# S32R372 register map
Vendor: Freescale Semiconductor, Inc.; Series: Qorivva; File version: 1.6
Registers are 32-bit, read-write, reset 0x0 unless marked. A register's access mark holds for its fields unless they carry their own. Offsets are from the block's base; [hi:lo] are bit positions; {n}, {i} and the like mark numbered series; 'fields as' and 'values as' point back to an identical list.

## STCU2
Base 0xFFF44000; register names take the prefix STCU2_
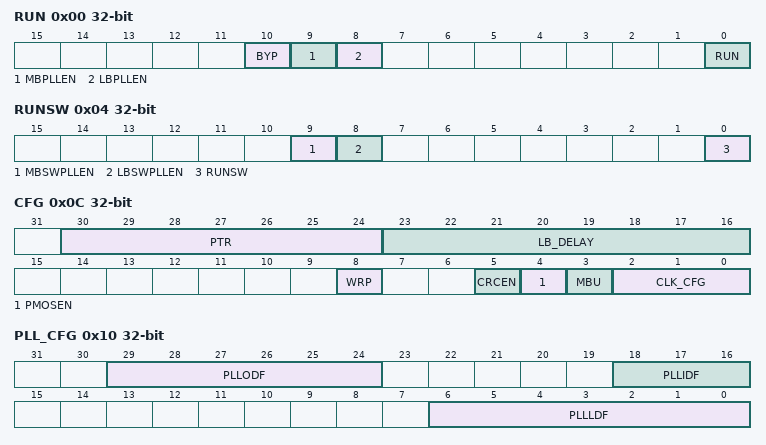
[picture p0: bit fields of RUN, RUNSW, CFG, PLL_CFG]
0x00 RUN — STCU2 Run Register
  [10] BYP — Bypass mode
    0=Off-Line Self-Test is active. In case the RUN bit into the STCU2_RUN register is not set before the Hard-Coded WDG Time-out, the WDTO error is generated into the STCU2_ERR_STAT register.; 1=Off-Line Self-Test is completely bypassed and the access to STCU2 is locked until the STCU2_SKC register is written according to the request access mode
  [9] MBPLLEN — Off-Line MBIST with PLL Enabled
    0=Off-Line MBIST is executed without using the on-chip PLL; 1=Off-Line MBIST is executed enabling the on-chip PLL control interface selecting the parameters defined into STCU2_PLL_CFG register
  [8] LBPLLEN — Off-Line LBIST with PLL Enabled
    0=Off-Line LBIST is executed without using the on-chip PLL; 1=Off-Line LBIST is executed enabling the on-chip PLL control interface selecting the parameters defined into STCU2_PLL_CFG register
  [0] RUN — RUN: RUN The RUN bit is automatically cleared by the STCU2 when the off-line self testing procedure has been completed
    0=Idle; 1=Off-Line Self testing procedure is running
0x04 RUNSW — STCU2 Run Software Register
  [9] MBSWPLLEN — On-Line MBIST with PLL Enabled
    0=On-Line MBIST is executed without using the on-chip PLL; 1=On-Line MBIST is executed using the PLL configuration provided by software. STCU2 does not take the PLL control but monitors the PLL lock signal to check if PLL is working correctly.
  [8] LBSWPLLEN — On-Line LBIST with PLL Enabled
    0=On-Line LBIST is executed without using the on-chip PLL; 1=On-Line LBIST is executed using the PLL configuration provided by software. STCU2 does not take the PLL control but monitors the PLL lock signal to check if PLL is working correctly.
  [0] RUNSW — RUNSW The RUNSW bit is automatically cleared by the STCU2 when the on-line self testing procedure has been completed
    0=Idle; 1=On-line self testing procedure is running
0x08 SKC wo — STCU2 SK Code Register
  [31:0] SKC — STCU2 security key code for off-line Test = D3FEA98Bh: Key1 to unlock the write access the STCU2 = 2C015674h: Key2 to unlock the write access the STCU2 STCU2 security key code for on-line Test = 753F924Eh: Key1 to unlock the write access the STCU2 = 8AC06DB1h: Key2 to unlock the write access the STCU2
0x0C CFG reset not defined — STCU2 Configuration Register
  [30:24] PTR — LBIST or MBIST pointer PTR defines the logical pointer to the first LBIST or MBIST to be scheduled when the self testing procedure is enabled
  [23:16] LB_DELAY — Delay LBIST run LB_DELAY defines the delay between the LBIST starts when more than a single LBIST is selected to be executed concurrently with the purpose of smoothing the power consumption transient
  [8] WRP — Write Protection 0: Specific STCU2 registers can be written through IPS bus interface after Off-Line Self-Test sequence has been completed 1: Specific STCU2 registers cannot be written though IPS also after Off-Line Self-Test sequence has been completed preventing in such a way any user application write operation
  [5] CRCEN — CRCEN: CRC Enable comparison You can always read this field
    0=The CRC comparison is not performed and the STCU2_ERR_STAT.CRCS[SW] and STCU2_ERR_STAT.UF/RF global flags are not updated in case of mismatches between STCU2.CRCE and STCU2.CRCR values; 1=The CRC comparison is performed and the status is updated into the related flags of the STCU2_ERR_STAT register
  [4] PMOSEN — MBIST PMOS Test Enable When MBU is 1 then "Auto test" MBIST test type will be selected regardless of the setting of this field
    0=When MBU is 0 then selects the "Reduced test" MBIST test type; 1=When MBU is 0 then selects the "Full test" MBIST test type
  [3] MBU — MBIST MBU Test Enabled
    0=Either "Full test" or "Reduced test" MBIST test type will be selected according to the PMOSEN value; 1=Selects "Auto test" MBIST test type regardless of the PMOSEN value
  [2:0] CLK_CFG — Logic, Memory BIST and STCU2 core CLK Clock configuration CLK_CFG defines the ratio between the sys_clk and the TCK used to program both the LBIST and the MBIST and the STCU2 core clock
0x10 PLL_CFG reset not defined — STCU2 PLL Configuration Register
  [29:24] PLLODF — PLL Output Division Factor The value of this field drives the Output Division factor of the PLL embedded into the device
  [18:16] PLLIDF — PLL Input Division Factor The value of this field drives the Input Division factor of the PLL embedded into the device
  [6:0] PLLLDF — PLL Loop Division Factor The value of this field drives the Loop Division factor of the PLL embedded into the device
0x14 WDG — STCU2 Watchdog Granularity
  [31:0] WDGEOC — Watchdog End of Count Timer This value defines the time limit for offline and online self test execution to ensure correct operation within the allowed time
0x1C CRCE reset not defined — STCU2 CRC Expected Status Register
  [31:0] CRCE — CRC expected signature
0x20 CRCR ro — STCU2 CRC Read Status Register
  [31:0] CRCR — Read CRC signature
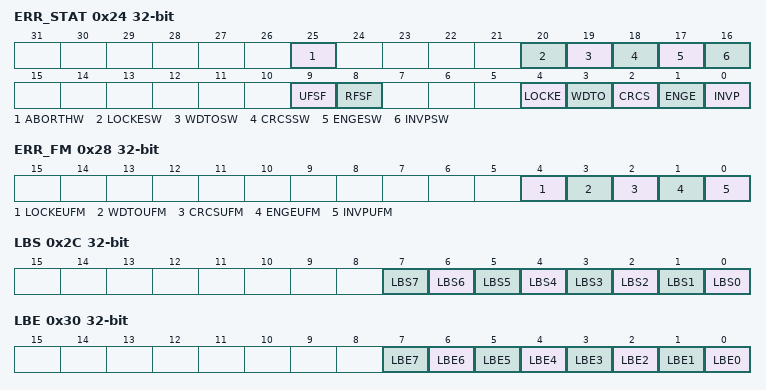
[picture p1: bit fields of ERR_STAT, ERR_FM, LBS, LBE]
0x24 ERR_STAT — STCU2 Error Register
  [25] ABORTHW ro — On-line hardware abort flag You can always read this field
    0=No hardware abort was requested during the On-Life Self-Test sequence; 1=A hardware abort was detected during the On-Life Self-Test sequence
  [20] LOCKESW ro — On-Line LOCK Error You can always read this field
    0=In case PLL is enabled, it is correctly locked during the Self-Test sequence; 1=When the PLL is enabled, this flag highlight that there has been an unexpected PLL unlock event during the On-Line Self-Test sequence execution. The On-Line Self-test run is stopped and the status of the current running LBISTs or MBISTs is saved into the related registers. The LOCK signal is monitored during the LBIST run when STCU2_RUNSW.LBSWPLLEN is set and/or during the MBIST run when STCU2_RUNSW[MBSWPLLEN] = 1.
  [19] WDTOSW ro — On-Line Watchdog time-out You can always read this field
    0=LBIST and MBIST time slot have been completed within the assigned watchdog time; 1=LBIST and MBIST time slot haven't been completed within the assigned watchdog time or there are internal mismatches among End of Execution signals. The conditions that flag the failures are the following: MBIST BEND status flags that at least one of the selected MBIST run is not finished lbist_done of the selected LBIST flags the LBIST run is/are not finished
  [18] CRCSSW ro — On-Line CRC Status This flag is activated ONLY when On-Line Self Test is performed and STCU2_CFG
    0=Successful CRC comparison or comparison has been masked (STCU2_CFG.CRCEN set to 0); 1=Failed CRC comparison
  [17] ENGESW ro — On-Line Engine Error You can always read this field
    0=Valid Engine execution; 1=Invalid Engine execution. The following conditions set this bit: STCU2 state machines (Watchdog, Master and Loader/Shifter) selects an unused code Serial pass/fail status of the selected MBIST and the global BBAD flag are not aligned Serial bend status of the selected MBIST and the global BEND flag are not aligned
  [16] INVPSW ro — On-Line Invalid Pointer You can always read this field
    0=Valid linked pointer list; 1=Invalid linked pointer list. The following conditions set this bit: Initial LBIST or MBIST pointer is out of range LBIST is selected when MBIST is concurrently running or vice versa Error in the LBIST/MBIST linking (execution generates an infinite loop)
  [9] UFSF — Unrecoverable Faults Status Flag This flag reports the global status of the UF
    0=No errors that trigger the Unrecoverable Faults condition; 1=There are errors that trigger the Unrecoverable Faults condition
  [8] RFSF — Recoverable Faults Status Flag This flag reports the global status of the RF
    0=No errors that trigger the Recoverable Faults condition; 1=There are errors that trigger the Recoverable Faults condition
  [4] LOCKE ro — Off-Line LOCK Error
    0=The PLL is correctly locked during the Self-Test sequence; 1=When the PLL is enabled, this flag highlights that there has been an unexpected PLL unlock event during the Off-Line Self-Test sequence execution. The Off-Line Self-test run is stopped and the status of the current running LBISTs or MBISTs is saved into the related registers. The LOCK signal is monitored during the LBIST run when STCU2_RUN[LBPLLEN] = 1 and/or during the MBIST run when STCU2_RUN[MBPLLEN] = 1.
  [3] WDTO ro — Off-Line Watchdog time-out
    0=LBIST and MBIST time slot have been completed within the assigned watchdog time; 1=LBIST and MBIST time slot haven't been completed within the assigned watchdog time or there are internal mismatches among End of Execution signals. The conditions that flag the failures are the following: The STCU2_RUN[RUN] bit or the STCU2_RUN[BYP] bit is not set before the Watchdog reaches the End of Count MBIST BEND status flags that at least one of the selected MBIST run is not finished lbist_done of the selected LBIST flags the LBIST run is/are not finished
  [2] CRCS ro — Off-Line CRC status This flag is activated ONLY when Off-Line Self Test is performed STCU2_CFG[CRCEN] is set to 1 otherwise it is always forced to 0 preventing in such a way the generation of the related STCU2_ERR_STAT
    0=Successful CRC comparison or comparison has been masked (STCU2_CFG[CRCEN] programmed to 0); 1=Failed CRC comparison
  [1] ENGE ro — Off-Line Engine Error
    values as ENGESW
  [0] INVP ro — Off-Line Invalid pointer
    values as INVPSW
0x28 ERR_FM reset not defined — STCU2 Error FM Register
  [4] LOCKEUFM — PLL LOCK Unrecoverable Fault Mapping
    0=Recoverable Fault Mapping; 1=Unrecoverable Fault Mapping
  [3] WDTOUFM — Watchdog time-out Unrecoverable Fault Mapping
    0=Recoverable Fault Mapping; 1=Unrecoverable Fault Mapping
  [2] CRCSUFM — CRC Status Unrecoverable Fault Mapping
    0=Recoverable Fault Mapping; 1=Unrecoverable Fault Mapping
  [1] ENGEUFM — Engine Error Unrecoverable fault Mapping
    0=Recoverable Fault Mapping; 1=Unrecoverable Fault Mapping
  [0] INVPUFM — Invalid Pointer Unrecoverable Fault Mapping
    0=Recoverable Fault Mapping; 1=Unrecoverable Mapping
0x2C LBS ro — STCU2 Off-Line LBIST Status Register
  [all] fields
    0=Failed LBIST execution; 1=Successful LBIST execution
  [n] LBS{n} (n=0..7) — Off-Line status of the selected LBIST
0x30 LBE ro — STCU2 Off-Line LBIST End Flag Register
  [all] fields
    0=LBIST execution not yet completed; 1=LBIST execution finished
  [n] LBE{n} (n=0..7) — Off-Line End status of the selected LBIST
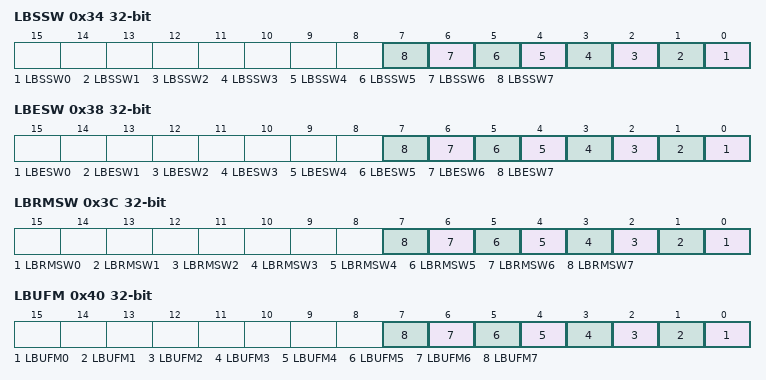
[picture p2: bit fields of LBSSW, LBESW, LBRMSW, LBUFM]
0x34 LBSSW ro — STCU2 On-Line LBIST Status Register
  [all] fields
    0=Failed LBIST execution; 1=Successful LBIST execution
  [n] LBSSW{n} (n=0..7) — LBSSWx: On-Line status of the selected LBIST
0x38 LBESW ro — STCU2 On-Line LBIST End Flag Register
  [all] fields
    values as the fields of LBE
  [n] LBESW{n} (n=0..7) — LBESWx: On-Line LBIST End status
0x3C LBRMSW reset not defined — STCU2 On-Line LBIST Reset Management
  [all] fields
    1=Global functional reset is pulsed at the end of LBIST run
  [n] LBRMSW{n} (n=0..7) — On-Line LBIST Reset Management In case one of the selected LBIST has this bit set to '1', then only the Global functional reset will be pulsed
0x40 LBUFM reset not defined — STCU2 LBIST Unrecoverable FM Register
  [all] fields
    0=Recoverable Fault mapping; 1=Unrecoverable Fault mapping
  [n] LBUFM{n} (n=0..7) — LBIST Unrecoverable Fault Mapping
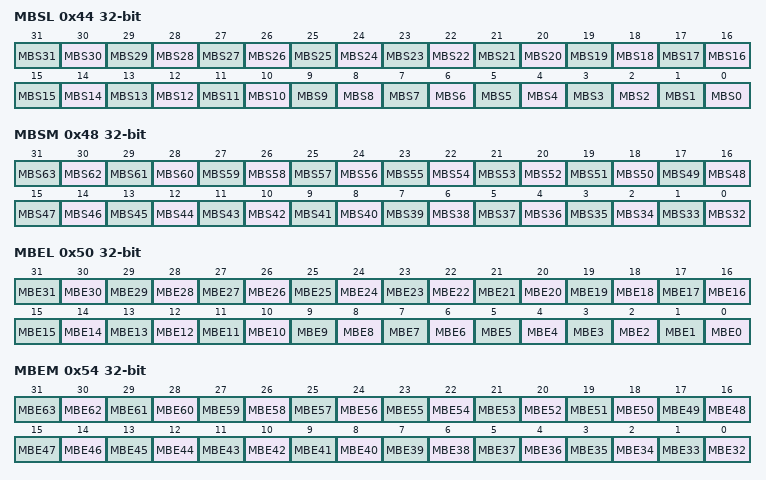
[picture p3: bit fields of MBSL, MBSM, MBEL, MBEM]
0x44 MBSL ro — STCU2 Off-Line MBIST Status Low Register
  [all] fields
    0=Failed NMCUT BIST execution; 1=No Fault detected during the NMCUT BIST execution
  [n] MBS{n} (n=0..31) — Off-Line status (NMCUT range = 0 to 31) of the selected MBIST This bit is meaningful when the related bit of the STCU2_MBEL register reports the MBIST is finished
0x48 MBSM ro — STCU2 Off-Line MBIST Status Medium Register
  [all] fields
    values as the fields of MBSL
  [n-32] MBS{n} (n=32..63) — MBSx: Off-Line status (NMCUT range = 32 to 63) of the selected MBIST This bit is meaningful when the related bit of the STCU2_MBEM register reports the MBIST is finished)
0x4C MBSH ro — STCU2 Off-Line MBIST Status High Register
  [0] MBS64 — Off-Line status (NMCUT range = 64 to 95) of the selected MBIST This bit is meaningful when the related bit of the STCU2_MBEH register reports the MBIST is finished)
    values as the fields of MBSL
0x50 MBEL ro — STCU2 Off-Line MBIST End Flag Low Register
  [all] fields
    0=MBIST execution still ongoing; 1=MBIST execution finished
  [n] MBE{n} (n=0..31) — Off-Line End status (0 to 31) of the selected MBIST
0x54 MBEM ro — STCU2 Off-Line MBIST End Flag Medium Register
  [all] fields
    0=MBIST execution still ongoing; 1=MBIST execution finished
  [n-32] MBE{n} (n=32..63) — Off-Line End status (32 to 63) of the selected MBIST
0x58 MBEH ro — STCU2 Off-Line MBIST End Flag High Register
  [0] MBE64 — MBEx: Off-Line End status (64 to 95) of the selected MBIST
    0=MBIST execution still ongoing; 1=MBIST execution finished
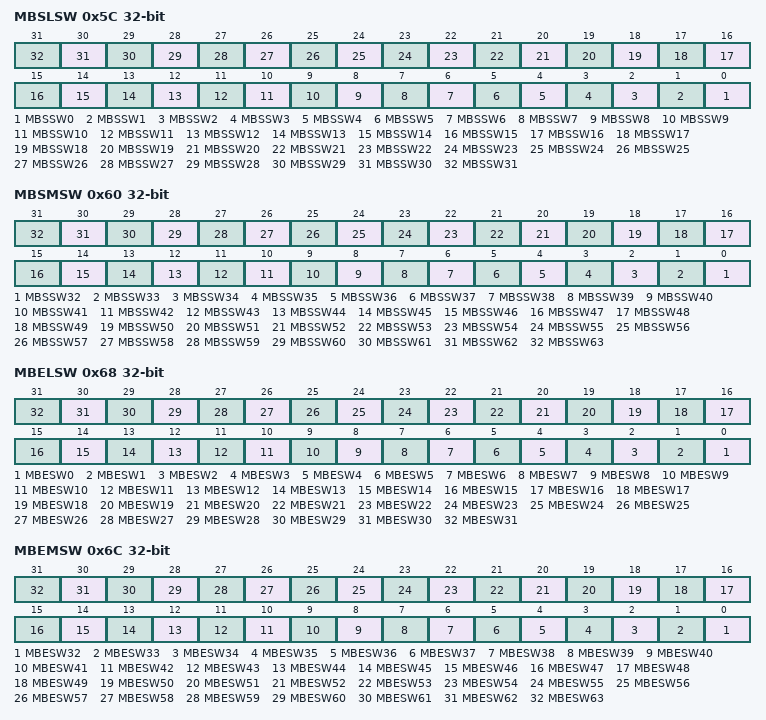
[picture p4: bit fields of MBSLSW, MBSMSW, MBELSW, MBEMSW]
0x5C MBSLSW ro — STCU2 On-Line MBIST Status Low Register
  [all] fields
    values as the fields of MBSL
  [n] MBSSW{n} (n=0..31) — On-Line status (NMCUT range = 0 to 31) of the selected MBIST
0x60 MBSMSW ro — STCU2 On-Line MBIST Status Medium Register
  [all] fields
    values as the fields of MBSL
  [n-32] MBSSW{n} (n=32..63) — MBSSWx: On-Line status (NMCUT range = 32 to 63) of the selected MBIST
0x64 MBSHSW ro — STCU2 On-Line MBIST Status High Register
  [0] MBSSW64 — MBSSWx: On-Line status (NMCUT range = 64 to 95) of the selected MBIST
    values as the fields of MBSL
0x68 MBELSW ro — STCU2 On-Line MBIST End Flag Low Register
  [all] fields
    0=MBIST execution still ongoing; 1=MBIST execution finished
  [n] MBESW{n} (n=0..31) — MBESWx: On-Line End status (0 to 31) of the selected MBIST
0x6C MBEMSW ro — STCU2 On-Line MBIST End Flag Medium Register
  [all] fields
    0=MBIST execution still ongoing; 1=MBIST execution finished
  [n-32] MBESW{n} (n=32..63) — On-Line End status (32 to 63) of the selected MBIST
0x70 MBEHSW ro — STCU2 On-Line MBIST End Flag High Register
  [0] MBESW64 — MBESWx: On-Line End status (64 to 95) of the selected MBIST
    0=MBIST execution still ongoing; 1=MBIST execution finished
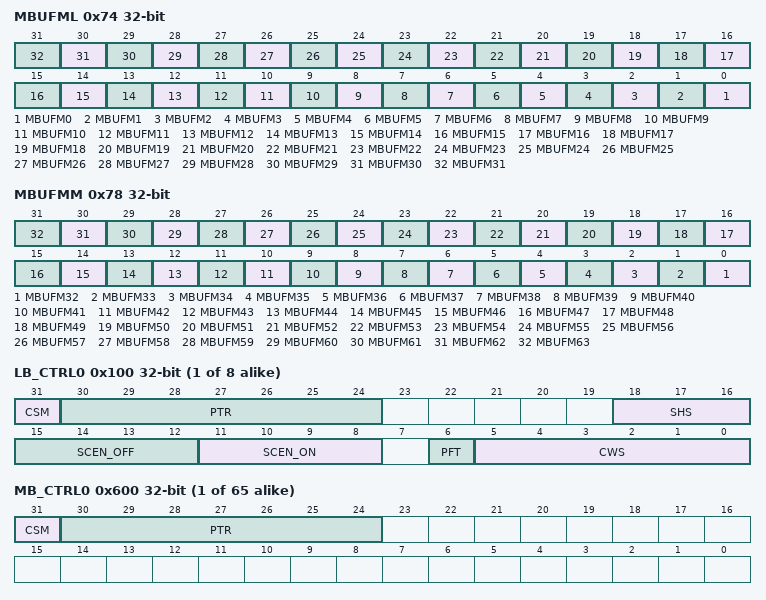
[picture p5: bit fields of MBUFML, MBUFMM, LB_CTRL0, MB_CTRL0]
0x74 MBUFML reset not defined — STCU2 MBIST Unrecoverable FM Low Register
  [all] fields
    0=Recoverable Fault mapping; 1=Unrecoverable Fault mapping
  [n] MBUFM{n} (n=0..31) — MBIST Unrecoverable Fault Mapping
0x78 MBUFMM reset not defined — STCU2 MBIST Unrecoverable FM Medium Register
  [all] fields
    0=Recoverable Fault mapping; 1=Unrecoverable Fault mapping
  [n-32] MBUFM{n} (n=32..63) — MBIST Unrecoverable Fault Mapping
0x7C MBUFMH reset not defined — STCU2 MBIST Unrecoverable FM High Register
  [0] MBUFM64 — MBIST Unrecoverable Fault Mapping
    0=Recoverable Fault mapping; 1=Unrecoverable Fault mapping
{0x100+0x40*i} LB_CTRL{i} (i=0..7) reset not defined — STCU2 LBIST Control
  [31] CSM — Concurrent/sequential mode The next LBIST is scheduled concurrently to the current one if the CSM bit is set to 1; otherwise, it is scheduled sequentially to the completion of the current LBIST execution
    0=Sequential mode; 1=Concurrent mode
  [30:24] PTR — Next LBIST pointer PTR defines the logical pointer to the next LBIST
  [18:16] SHS — Shift speed SHS defines the shift speed
    0=Shift at full rate of STCU2 core clock; {v}=Shift at 1/{v+1} rate of STCU2 core clock (v=1..7)
  [15:12] SCEN_OFF — Scan enable OFF SCEN_OFF defines the number of clock cycles OFF following the falling transition on the SCEN Scen_off must be programmed to a value >=1
    0=0 delay cycles; 1=1 delay cycle; {v}={v} delay cycles (v=2..15)
  [11:8] SCEN_ON — Scan enable ON SCEN_ON defines the number of clock cycles OFF following the rising transition on the SCEN Scen_on delay register value must be programmed to a value >=1>
    values as SCEN_OFF
  [6] PFT — Past Flush Test The LBIST controller, by default, applies 32 Flush Test patterns
  [5:0] CWS — Capture window size CWS defines the capture window size
{0x104+0x40*i} LB_PCS{i} (i=0..7) reset not defined — STCU2 LBIST PC Stop Register
  [25:0] PCS — Pattern counter stop PCS defines the pattern counter stop value.
{0x110+0x40*i} LB_MISREL{i} (i=0..7) reset not defined — STCU2 Off-Line LBIST MISR Expected Low Register
  [31:0] MISREx — Off-Line MISR Expected low Bits This field defines the low part (31..0) of the Expected MISR.
{0x114+0x40*i} LB_MISREH{i} (i=0..7) reset not defined — STCU2 Off-Line LBIST MISR Expected High Register
  [31:0] MISREx — Off-Line MISR Expected high Bits This field defines the high part (63-32) of the Expected MISR.
{0x118+0x40*i} LB_MISRRL{i} (i=0..7) ro reset not defined — STCU2 Off-Line LBIST MISR Read Low Register
  [31:0] MISRRx — Off-Line MISR Read Low Bits This field is equivalent to the Low Bits (31-0) of the MISR obtained at the end of the Off-Line LBIST execution
{0x11C+0x40*i} LB_MISRRH{i} (i=0..7) ro reset not defined — STCU2 Off-Line LBIST MISR Read High Register
  [31:0] MISRRx — Off-Line MISR Read High Bits This field is equivalent to the High Bits (63-32) of the MISR obtained at the end of the Off-Line LBIST execution
{0x120+0x40*i} LB_MISRELSW{i} (i=0..7) reset not defined — STCU2 On-Line LBIST MISR Expected Low Register
  [31:0] MISRESWx — On-Line MISR Expected low Bits This field defines the low part (31..0) of the Expected MISR.
{0x124+0x40*i} LB_MISREHSW{i} (i=0..7) reset not defined — STCU2 On-Line LBIST MISR Expected High Register
  [31:0] MISRESWx — On-Line MISR Expected high Bits This field defines the high part (63-32) of the Expected MISR.
{0x128+0x40*i} LB_MISRRLSW{i} (i=0..7) ro reset not defined — STCU2 On-Line LBIST MISR Read Low Register
  [31:0] MISRRSWx — On-Line MISR Read Low Bin This field is equivalent to the Low Bits (31-0) of the MISR obtained at the end of the Off-Line LBIST execution
{0x12C+0x40*i} LB_MISRRHSW{i} (i=0..7) ro reset not defined — STCU2 On-Line LBIST MISR Read High Register
  [31:0] MISRRSWx — On-Line MISR Read High Bits This field is equivalent to the Low Bits (63-32) of the MISR obtained at the end of the Off-Line LBIST execution
{0x600+4i} MB_CTRL{i} (i=0..64) reset not defined — STCU2 MBIST Control Register
  [31] CSM — Concurrent/sequential mode
    0=Sequential mode; 1=Concurrent mode
  [30:24] PTR — Next LBIST or MBIST pointer PTR defines the logical pointer to the next LBIST or MBIST to be scheduled
